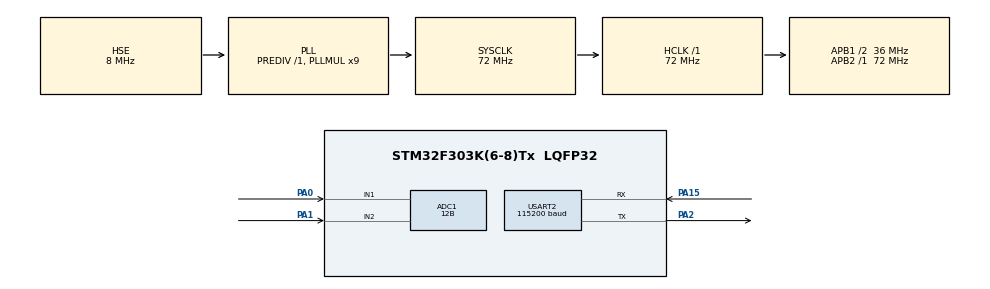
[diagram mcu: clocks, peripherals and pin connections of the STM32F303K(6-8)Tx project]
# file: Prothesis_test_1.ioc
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ADC1.Channel-0\#ChannelRegularConversion=ADC_CHANNEL_1
ADC1.Channel-16\#ChannelRegularConversion=ADC_CHANNEL_2
ADC1.ClockPrescaler=ADC_CLOCK_ASYNC_DIV1
ADC1.ContinuousConvMode=ENABLE
ADC1.DMAContinuousRequests=DISABLE
ADC1.DataAlign=ADC_DATAALIGN_RIGHT
ADC1.DiscontinuousConvMode=DISABLE
ADC1.EOCSelection=ADC_EOC_SINGLE_CONV
ADC1.EnableAnalogWatchDog1=false
ADC1.EnableAnalogWatchDog2=false
ADC1.EnableAnalogWatchDog3=false
ADC1.EnableInjectedConversion=ENABLE
ADC1.EnableRegularConversion=ENABLE
ADC1.ExternalTrigConv=ADC_SOFTWARE_START
ADC1.ExternalTrigConvEdge=ADC_EXTERNALTRIGCONVEDGE_NONE
ADC1.InjNumberOfConversion=0
ADC1.LowPowerAutoWait=DISABLE
ADC1.NbrOfConversion=2
ADC1.NbrOfConversionFlag=1
ADC1.Offset-0\#ChannelRegularConversion=0
ADC1.Offset-16\#ChannelRegularConversion=0
ADC1.OffsetNumber-0\#ChannelRegularConversion=ADC_OFFSET_NONE
ADC1.OffsetNumber-16\#ChannelRegularConversion=ADC_OFFSET_NONE
ADC1.Overrun=ADC_OVR_DATA_OVERWRITTEN
ADC1.Rank-0\#ChannelRegularConversion=1
ADC1.Rank-16\#ChannelRegularConversion=2
ADC1.Resolution=ADC_RESOLUTION_12B
ADC1.SamplingTime-0\#ChannelRegularConversion=ADC_SAMPLETIME_1CYCLE_5
ADC1.SamplingTime-16\#ChannelRegularConversion=ADC_SAMPLETIME_1CYCLE_5
ADC1.ScanConvMode=ADC_SCAN_ENABLE
ADC1.master=1
Mcu.Family=STM32F3
Mcu.Name=STM32F303K(6-8)Tx
Mcu.Package=LQFP32
NVIC.PriorityGroup=NVIC_PRIORITYGROUP_4
PA0.Mode=IN1-Single-Ended
PA0.Signal=ADC1_IN1
PA1.Mode=IN2-Single-Ended
PA1.Signal=ADC1_IN2
PA15.Mode=Asynchronous
PA15.Signal=USART2_RX
PA2.Mode=Asynchronous
PA2.Signal=USART2_TX
PF0\ /\ OSC_IN.GPIO_Label=MCO
PF0\ /\ OSC_IN.Mode=HSE-External-Clock-Source
PF0\ /\ OSC_IN.Signal=RCC_OSC_IN
ProjectManager.HeapSize=0x200
ProjectManager.StackSize=0x400
ProjectManager.TargetToolchain=SW4STM32
RCC.AHBFreq_Value=72000000
RCC.APB1CLKDivider=RCC_HCLK_DIV2
RCC.APB1Freq_Value=36000000
RCC.APB1TimFreq_Value=72000000
RCC.APB2Freq_Value=72000000
RCC.APB2TimFreq_Value=72000000
RCC.CortexFreq_Value=72000000
RCC.HCLKFreq_Value=72000000
RCC.HSE_VALUE=8000000
RCC.HSI_VALUE=8000000
RCC.PLLMUL=RCC_PLL_MUL9
RCC.PLLSourceVirtual=RCC_PLLSOURCE_HSE
RCC.SYSCLKFreq_VALUE=72000000
RCC.SYSCLKSourceVirtual=RCC_SYSCLKSOURCE_PLLCLK
USART2.BaudRate=115200
USART2.VirtualMode-Asynchronous=VM_ASYNC
board=NUCLEO-F303K8

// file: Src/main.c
/**
  ******************************************************************************
  * File Name          : main.c
  * Description        : Main program body
  ******************************************************************************
  ** This notice applies to any and all portions of this file
  * that are not between comment pairs USER CODE BEGIN and
  * USER CODE END. Other portions of this file, whether
  * inserted by the user or by software development tools
  * are owned by their respective copyright owners.
  *
  * COPYRIGHT(c) 2018 STMicroelectronics
  *
  * Redistribution and use in source and binary forms, with or without modification,
  * are permitted provided that the following conditions are met:
  *   1. Redistributions of source code must retain the above copyright notice,
  *      this list of conditions and the following disclaimer.
  *   2. Redistributions in binary form must reproduce the above copyright notice,
  *      this list of conditions and the following disclaimer in the documentation
  *      and/or other materials provided with the distribution.
  *   3. Neither the name of STMicroelectronics nor the names of its contributors
  *      may be used to endorse or promote products derived from this software
  *      without specific prior written permission.
  *
  * THIS SOFTWARE IS PROVIDED BY THE COPYRIGHT HOLDERS AND CONTRIBUTORS "AS IS"
  * AND ANY EXPRESS OR IMPLIED WARRANTIES, INCLUDING, BUT NOT LIMITED TO, THE
  * IMPLIED WARRANTIES OF MERCHANTABILITY AND FITNESS FOR A PARTICULAR PURPOSE ARE
  * DISCLAIMED. IN NO EVENT SHALL THE COPYRIGHT HOLDER OR CONTRIBUTORS BE LIABLE
  * FOR ANY DIRECT, INDIRECT, INCIDENTAL, SPECIAL, EXEMPLARY, OR CONSEQUENTIAL
  * DAMAGES (INCLUDING, BUT NOT LIMITED TO, PROCUREMENT OF SUBSTITUTE GOODS OR
  * SERVICES; LOSS OF USE, DATA, OR PROFITS; OR BUSINESS INTERRUPTION) HOWEVER
  * CAUSED AND ON ANY THEORY OF LIABILITY, WHETHER IN CONTRACT, STRICT LIABILITY,
  * OR TORT (INCLUDING NEGLIGENCE OR OTHERWISE) ARISING IN ANY WAY OUT OF THE USE
  * OF THIS SOFTWARE, EVEN IF ADVISED OF THE POSSIBILITY OF SUCH DAMAGE.
  *
  ******************************************************************************
  */

#include "main.h"
#include "stm32f3xx_hal.h"

ADC_HandleTypeDef hadc1;

UART_HandleTypeDef huart2;

/* USER CODE BEGIN PV */
/* Private variables ---------------------------------------------------------*/

/* USER CODE END PV */

void SystemClock_Config(void);
static void MX_GPIO_Init(void);
static void MX_ADC1_Init(void);
static void MX_USART2_UART_Init(void);

/* USER CODE BEGIN PFP */
/* Private function prototypes -----------------------------------------------*/

/* USER CODE END PFP */

int main(void)
{

  /* MCU Configuration----------------------------------------------------------*/

  /* Reset of all peripherals, Initializes the Flash interface and the Systick. */
  HAL_Init();

  /* Configure the system clock */
  SystemClock_Config();

  /* Initialize all configured peripherals */
  MX_GPIO_Init();
  MX_ADC1_Init();
  MX_USART2_UART_Init();
// ADC_ChannelConfTypeDef sConfig;

  /* USER CODE BEGIN 2 */
  uint32_t Toe_val=0;
  uint32_t Heel_val=0;
  uint32_t length;
  uint8_t temp[64] = {0};
  uint8_t str[64];
  /* USER CODE END 2 */

  /* Infinite loop */
  /* USER CODE BEGIN WHILE */
  while (1)
  {
	  HAL_ADC_Start(&hadc1);
/*
	  sConfig.Channel = ADC_CHANNEL_1;
	  Toe_val = HAL_ADC_GetValue(&hadc1);
	  sprintf(temp, "toe = %d\r\n", Toe_val);
	  length=strlen(temp);
	  memcpy(str,&temp,length);
	  HAL_UART_Transmit(&huart2, str, length, 0xffff);
*/
	  HAL_Delay(10);

	  Heel_val = HAL_ADCEx_MultiModeGetValue  ( &hadc1 );
//	  Heel_val = HAL_ADC_GetValue(&hadc1);
	  sprintf(temp, "Heel = %d\r\n", Heel_val);
	  length=strlen(temp);
	  memcpy(str,&temp,length);
	  HAL_UART_Transmit(&huart2, str, length, 0xffff);

	  /* USER CODE END WHILE */

  }

}

/** System Clock Configuration
*/
void SystemClock_Config(void)
{

  RCC_OscInitTypeDef RCC_OscInitStruct;
  RCC_ClkInitTypeDef RCC_ClkInitStruct;
  RCC_PeriphCLKInitTypeDef PeriphClkInit;

    /**Initializes the CPU, AHB and APB busses clocks
    */
  RCC_OscInitStruct.OscillatorType = RCC_OSCILLATORTYPE_HSE;
  RCC_OscInitStruct.HSEState = RCC_HSE_BYPASS;
  RCC_OscInitStruct.HSEPredivValue = RCC_HSE_PREDIV_DIV1;
  RCC_OscInitStruct.HSIState = RCC_HSI_ON;
  RCC_OscInitStruct.PLL.PLLState = RCC_PLL_ON;
  RCC_OscInitStruct.PLL.PLLSource = RCC_PLLSOURCE_HSE;
  RCC_OscInitStruct.PLL.PLLMUL = RCC_PLL_MUL9;
  if (HAL_RCC_OscConfig(&RCC_OscInitStruct) != HAL_OK)
  {
    _Error_Handler(__FILE__, __LINE__);
  }

    /**Initializes the CPU, AHB and APB busses clocks
    */
  RCC_ClkInitStruct.ClockType = RCC_CLOCKTYPE_HCLK|RCC_CLOCKTYPE_SYSCLK
                              |RCC_CLOCKTYPE_PCLK1|RCC_CLOCKTYPE_PCLK2;
  RCC_ClkInitStruct.SYSCLKSource = RCC_SYSCLKSOURCE_PLLCLK;
  RCC_ClkInitStruct.AHBCLKDivider = RCC_SYSCLK_DIV1;
  RCC_ClkInitStruct.APB1CLKDivider = RCC_HCLK_DIV2;
  RCC_ClkInitStruct.APB2CLKDivider = RCC_HCLK_DIV1;

  if (HAL_RCC_ClockConfig(&RCC_ClkInitStruct, FLASH_LATENCY_2) != HAL_OK)
  {
    _Error_Handler(__FILE__, __LINE__);
  }

  PeriphClkInit.PeriphClockSelection = RCC_PERIPHCLK_ADC12;
  PeriphClkInit.Adc12ClockSelection = RCC_ADC12PLLCLK_DIV1;
  if (HAL_RCCEx_PeriphCLKConfig(&PeriphClkInit) != HAL_OK)
  {
    _Error_Handler(__FILE__, __LINE__);
  }

    /**Configure the Systick interrupt time
    */
  HAL_SYSTICK_Config(HAL_RCC_GetHCLKFreq()/1000);

    /**Configure the Systick
    */
  HAL_SYSTICK_CLKSourceConfig(SYSTICK_CLKSOURCE_HCLK);

  /* SysTick_IRQn interrupt configuration */
  HAL_NVIC_SetPriority(SysTick_IRQn, 0, 0);
}

/* ADC1 init function */
static void MX_ADC1_Init(void)
{

  ADC_MultiModeTypeDef multimode;
  ADC_ChannelConfTypeDef sConfig;

    /**Common config
    */
  hadc1.Instance = ADC1;
  hadc1.Init.ClockPrescaler = ADC_CLOCK_ASYNC_DIV1;
  hadc1.Init.Resolution = ADC_RESOLUTION_12B;
  hadc1.Init.ScanConvMode = ADC_SCAN_ENABLE;
  hadc1.Init.ContinuousConvMode = ENABLE;
  hadc1.Init.DiscontinuousConvMode = DISABLE;
  hadc1.Init.ExternalTrigConvEdge = ADC_EXTERNALTRIGCONVEDGE_NONE;
  hadc1.Init.ExternalTrigConv = ADC_SOFTWARE_START;
  hadc1.Init.DataAlign = ADC_DATAALIGN_RIGHT;
  hadc1.Init.NbrOfConversion = 2;
  hadc1.Init.DMAContinuousRequests = DISABLE;
  hadc1.Init.EOCSelection = ADC_EOC_SINGLE_CONV;
  hadc1.Init.LowPowerAutoWait = DISABLE;
  hadc1.Init.Overrun = ADC_OVR_DATA_OVERWRITTEN;
  if (HAL_ADC_Init(&hadc1) != HAL_OK)
  {
    _Error_Handler(__FILE__, __LINE__);
  }

    /**Configure the ADC multi-mode
    */
  multimode.Mode = ADC_MODE_INDEPENDENT;
  if (HAL_ADCEx_MultiModeConfigChannel(&hadc1, &multimode) != HAL_OK)
  {
    _Error_Handler(__FILE__, __LINE__);
  }

    /**Configure Regular Channel
    */
  sConfig.Channel = ADC_CHANNEL_1;
  sConfig.Rank = 1;
  sConfig.SingleDiff = ADC_SINGLE_ENDED;
  sConfig.SamplingTime = ADC_SAMPLETIME_1CYCLE_5;
  sConfig.OffsetNumber = ADC_OFFSET_NONE;
  sConfig.Offset = 0;
  if (HAL_ADC_ConfigChannel(&hadc1, &sConfig) != HAL_OK)
  {
    _Error_Handler(__FILE__, __LINE__);
  }

    /**Configure Regular Channel
    */
  sConfig.Channel = ADC_CHANNEL_2;
  sConfig.Rank = 2;
  if (HAL_ADC_ConfigChannel(&hadc1, &sConfig) != HAL_OK)
  {
    _Error_Handler(__FILE__, __LINE__);
  }

}

/* USART2 init function */
static void MX_USART2_UART_Init(void)
{

  huart2.Instance = USART2;
  huart2.Init.BaudRate = 115200;
  huart2.Init.StopBits = UART_STOPBITS_1;
  huart2.Init.Parity = UART_PARITY_NONE;
  huart2.Init.Mode = UART_MODE_TX_RX;
  huart2.Init.HwFlowCtl = UART_HWCONTROL_NONE;
  huart2.Init.OverSampling = UART_OVERSAMPLING_16;
  huart2.Init.OneBitSampling = UART_ONE_BIT_SAMPLE_DISABLE;
  huart2.AdvancedInit.AdvFeatureInit = UART_ADVFEATURE_NO_INIT;
  if (HAL_UART_Init(&huart2) != HAL_OK)
  {
    _Error_Handler(__FILE__, __LINE__);
  }

}

/** Configure pins as
        * Analog
        * Input
        * Output
        * EVENT_OUT
        * EXTI
*/
static void MX_GPIO_Init(void)
{

  /* GPIO Ports Clock Enable */
  __HAL_RCC_GPIOF_CLK_ENABLE();
  __HAL_RCC_GPIOA_CLK_ENABLE();

}

void _Error_Handler(char * file, int line)
{
  while(1)
  {
  }
}

/************************ (C) COPYRIGHT STMicroelectronics *****END OF FILE****/
